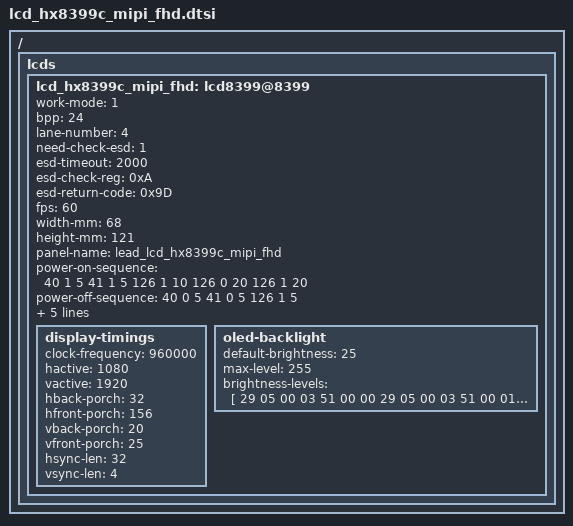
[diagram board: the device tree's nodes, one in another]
/ { lcds {
lcd_hx8399c_mipi_fhd: lcd8399@8399 {

		work-mode = <1>;
		bpp = <24>;
		lane-number = <4>;

		need-check-esd = <1>;
		esd-timeout = <2000>;
		esd-check-reg = <0xA>;
		esd-return-code = <0x9D>;

		fps = <60>;
		width-mm = <68>;
		height-mm = <121>;
		panel-name = "lead_lcd_hx8399c_mipi_fhd";

		power-on-sequence = <
				40  1  5
				41  1  5
				126  1  10
				126  0  20
				126  1  20
				>;
		power-off-sequence = <
				40  0  5
				41  0  5
				126  1  5
				>;

		init-data = [
			29 00 00 04 B9 FF 83 99
			29 00 00 05 BA 63 03 68 73
			29 00 00 10 B1 02 04 6D 8D 01 32 33 11 11 5E 64 56 73 02 02
			29 00 00 10 B2 07 00 80 AE 05 07 5A 31 10 30 00 1E 70 03 D4
			29 00 00 2D B4 00 FF 10 18 04 9A 00 00 06 00 02 04 00 24 02 04 0A 21 03 00 00 02 9F 88 10 18 04 9A 00 00 08 00 02 04 00 24 02 04 0A 00 00 02 9F 12
			29 00 00 22 D3 00 00 00 00 00 00 30 00 00 00 05 00 05 00 07 88 07 88 00 00 00 00 00 14 00 00 00 01 00 00 00 05 40
			29 00 00 21 D5 20 20 1E 1E 1F 1F 01 01 00 00 25 25 18 18 18 18 24 24 18 18 18 18 18 18 18 18 2F 2F 30 30 31 31
			29 00 00 21 D6 24 24 1E 1E 1F 1F 00 00 01 01 25 25 18 18 18 18 20 20 18 18 18 18 18 18 18 18 2F 2F 30 30 31 31
			23 00 00 02 BD 00
			29 00 00 11 D8 AA 8A AA AA AA 8A AA AA AA 8A AA AA AA 8A AA AA
			23 00 00 02 BD 01
			29 00 00 11 D8 FF CF EA BF FF CF EA BF FF CF EA BF FF CF EA BF
			23 00 00 02 BD 02
			29 00 00 09 D8 FF CF EA BF FF CF EA BF
			23 00 00 02 BD 00
			29 00 00 06 C9 03 00 12 20 31
			29 00 00 37 E0 02 1D 2B 25 54 5F 6C 69 72 7B 82 8A 90 98 9F A4 A5 AC AD B3 A4 AF B1 5B 59 65 7C 02 1D 2B 25 54 5F 6C 6A 73 7A 84 8B 90 96 9C 9F A0 A9 AC B2 A4 AF B1 5A 51 59 7C
			29 00 00 03 B6 8A 8A
			23 00 00 02 CC 08
			29 00 00 06 C7 00 08 00 01 08
			29 00 00 03 C0 25 5A
			29 00 00 08 BF 40 41 50 09 1A C0 CD
			23 0A 00 02 E4 01
			23 78 00 02 11 00
			23 14 00 02 29 00
			29 08 00 03 E4 01 02
			29 01 00 0A E5 00 04 0B 08 06 00 20 20 00
			29 01 00 0D E6 00 00 00 05 05 10 0A 10 20 20 00 00
			29 05 00 03 51 00 00
			23 05 00 02 55 01
			29 05 00 0A CA 24 24 24 23 23 20 20 20 20
			23 05 00 02 53 2C
			];
		sleep-in = [
			23 05 00 02 53 24
			29 00 00 04 B9 FF 83 99
			23 05 00 02 B1 00
			13 32 00 01 28
			13 A0 00 01 10
			29 00 00 04 B9 FF 83 99
			23 05 00 02 B1 01
			];
		sleep-out = [
			13 78 00 01 11
			13 32 00 01 29
			];

		display-timings {
			clock-frequency = <960000>;
			hactive = <1080>;
			vactive = <1920>;
			hback-porch = <32>;
			hfront-porch = <156>;
			vback-porch = <20>;
			vfront-porch = <25>;
			hsync-len = <32>;
			vsync-len = <4>;
		};
		oled-backlight {
			default-brightness = <25>;
			max-level = <255>;
			brightness-levels = [
				29 05 00 03 51 00 00
				29 05 00 03 51 00 01
				29 05 00 03 51 00 02
				29 05 00 03 51 00 03
				29 05 00 03 51 00 04
				29 05 00 03 51 00 06
				29 05 00 03 51 00 08
				29 05 00 03 51 00 0A
				29 05 00 03 51 00 0C
				29 05 00 03 51 00 0E
				29 05 00 03 51 00 10
				29 05 00 03 51 00 1A
				29 05 00 03 51 00 24
				29 05 00 03 51 00 2E
				29 05 00 03 51 00 39
				29 05 00 03 51 00 43
				29 05 00 03 51 00 4D
				29 05 00 03 51 00 58
				29 05 00 03 51 00 62
				29 05 00 03 51 00 6C
				29 05 00 03 51 00 76
				29 05 00 03 51 00 81
				29 05 00 03 51 00 8B
				29 05 00 03 51 00 95
				29 05 00 03 51 00 A0
				29 05 00 03 51 00 AA
				29 05 00 03 51 00 B4
				29 05 00 03 51 00 BE
				29 05 00 03 51 00 C9
				29 05 00 03 51 00 D3
				29 05 00 03 51 00 DD
				29 05 00 03 51 00 E8
				29 05 00 03 51 00 F2
				29 05 00 03 51 00 FC
				29 05 00 03 51 01 07
				29 05 00 03 51 01 11
				29 05 00 03 51 01 1B
				29 05 00 03 51 01 25
				29 05 00 03 51 01 30
				29 05 00 03 51 01 3A
				29 05 00 03 51 01 44
				29 05 00 03 51 01 4F
				29 05 00 03 51 01 59
				29 05 00 03 51 01 63
				29 05 00 03 51 01 6D
				29 05 00 03 51 01 78
				29 05 00 03 51 01 82
				29 05 00 03 51 01 8C
				29 05 00 03 51 01 97
				29 05 00 03 51 01 A1
				29 05 00 03 51 01 AB
				29 05 00 03 51 01 B6
				29 05 00 03 51 01 C0
				29 05 00 03 51 01 CA
				29 05 00 03 51 01 D4
				29 05 00 03 51 01 DF
				29 05 00 03 51 01 E9
				29 05 00 03 51 01 F3
				29 05 00 03 51 01 FE
				29 05 00 03 51 02 08
				29 05 00 03 51 02 12
				29 05 00 03 51 02 1C
				29 05 00 03 51 02 27
				29 05 00 03 51 02 31
				29 05 00 03 51 02 3B
				29 05 00 03 51 02 46
				29 05 00 03 51 02 50
				29 05 00 03 51 02 5A
				29 05 00 03 51 02 65
				29 05 00 03 51 02 6F
				29 05 00 03 51 02 79
				29 05 00 03 51 02 83
				29 05 00 03 51 02 8E
				29 05 00 03 51 02 98
				29 05 00 03 51 02 A2
				29 05 00 03 51 02 AD
				29 05 00 03 51 02 B7
				29 05 00 03 51 02 C1
				29 05 00 03 51 02 CB
				29 05 00 03 51 02 D6
				29 05 00 03 51 02 E0
				29 05 00 03 51 02 EA
				29 05 00 03 51 02 F5
				29 05 00 03 51 02 FF
				29 05 00 03 51 03 09
				29 05 00 03 51 03 14
				29 05 00 03 51 03 1E
				29 05 00 03 51 03 28
				29 05 00 03 51 03 32
				29 05 00 03 51 03 3D
				29 05 00 03 51 03 47
				29 05 00 03 51 03 51
				29 05 00 03 51 03 5C
				29 05 00 03 51 03 66
				29 05 00 03 51 03 70
				29 05 00 03 51 03 7A
				29 05 00 03 51 03 85
				29 05 00 03 51 03 8F
				29 05 00 03 51 03 99
				29 05 00 03 51 03 A4
				29 05 00 03 51 03 AE
				29 05 00 03 51 03 B8
				29 05 00 03 51 03 C3
				29 05 00 03 51 03 C9
				29 05 00 03 51 03 CF
				29 05 00 03 51 03 D6
				29 05 00 03 51 03 DC
				29 05 00 03 51 03 E3
				29 05 00 03 51 03 E9
				29 05 00 03 51 03 F0
				29 05 00 03 51 03 F6
				29 05 00 03 51 03 FC
				29 05 00 03 51 04 03
				29 05 00 03 51 04 09
				29 05 00 03 51 04 10
				29 05 00 03 51 04 16
				29 05 00 03 51 04 1D
				29 05 00 03 51 04 23
				29 05 00 03 51 04 2A
				29 05 00 03 51 04 30
				29 05 00 03 51 04 36
				29 05 00 03 51 04 3D
				29 05 00 03 51 04 43
				29 05 00 03 51 04 4A
				29 05 00 03 51 04 50
				29 05 00 03 51 04 57
				29 05 00 03 51 04 5D
				29 05 00 03 51 04 64
				29 05 00 03 51 04 71
				29 05 00 03 51 04 7F
				29 05 00 03 51 04 8D
				29 05 00 03 51 04 9B
				29 05 00 03 51 04 A8
				29 05 00 03 51 04 B6
				29 05 00 03 51 04 C4
				29 05 00 03 51 04 D2
				29 05 00 03 51 04 E0
				29 05 00 03 51 04 ED
				29 05 00 03 51 04 FB
				29 05 00 03 51 05 09
				29 05 00 03 51 05 17
				29 05 00 03 51 05 25
				29 05 00 03 51 05 32
				29 05 00 03 51 05 40
				29 05 00 03 51 05 4E
				29 05 00 03 51 05 5C
				29 05 00 03 51 05 6A
				29 05 00 03 51 05 77
				29 05 00 03 51 05 85
				29 05 00 03 51 05 93
				29 05 00 03 51 05 A1
				29 05 00 03 51 05 AF
				29 05 00 03 51 05 BC
				29 05 00 03 51 05 CA
				29 05 00 03 51 05 D8
				29 05 00 03 51 05 E6
				29 05 00 03 51 05 F4
				29 05 00 03 51 06 01
				29 05 00 03 51 06 0F
				29 05 00 03 51 06 1D
				29 05 00 03 51 06 2B
				29 05 00 03 51 06 39
				29 05 00 03 51 06 46
				29 05 00 03 51 06 54
				29 05 00 03 51 06 62
				29 05 00 03 51 06 70
				29 05 00 03 51 06 7E
				29 05 00 03 51 06 8B
				29 05 00 03 51 06 99
				29 05 00 03 51 06 A7
				29 05 00 03 51 06 B5
				29 05 00 03 51 06 C3
				29 05 00 03 51 06 D0
				29 05 00 03 51 06 DE
				29 05 00 03 51 06 EC
				29 05 00 03 51 06 FA
				29 05 00 03 51 07 08
				29 05 00 03 51 07 15
				29 05 00 03 51 07 23
				29 05 00 03 51 07 31
				29 05 00 03 51 07 3F
				29 05 00 03 51 07 4D
				29 05 00 03 51 07 5A
				29 05 00 03 51 07 68
				29 05 00 03 51 07 76
				29 05 00 03 51 07 84
				29 05 00 03 51 07 92
				29 05 00 03 51 07 9F
				29 05 00 03 51 07 AD
				29 05 00 03 51 07 BB
				29 05 00 03 51 07 C9
				29 05 00 03 51 07 D7
				29 05 00 03 51 07 E4
				29 05 00 03 51 07 F2
				29 05 00 03 51 08 00
				29 05 00 03 51 08 0E
				29 05 00 03 51 08 1B
				29 05 00 03 51 08 29
				29 05 00 03 51 08 37
				29 05 00 03 51 08 45
				29 05 00 03 51 08 53
				29 05 00 03 51 08 60
				29 05 00 03 51 08 6E
				29 05 00 03 51 08 7C
				29 05 00 03 51 08 8A
				29 05 00 03 51 08 98
				29 05 00 03 51 08 A5
				29 05 00 03 51 08 B3
				29 05 00 03 51 08 C1
				29 05 00 03 51 08 CF
				29 05 00 03 51 08 DD
				29 05 00 03 51 08 EA
				29 05 00 03 51 08 F8
				29 05 00 03 51 09 06
				29 05 00 03 51 09 14
				29 05 00 03 51 09 22
				29 05 00 03 51 09 2F
				29 05 00 03 51 09 3D
				29 05 00 03 51 09 4B
				29 05 00 03 51 09 59
				29 05 00 03 51 09 67
				29 05 00 03 51 09 74
				29 05 00 03 51 09 82
				29 05 00 03 51 09 90
				29 05 00 03 51 09 9E
				29 05 00 03 51 09 AC
				29 05 00 03 51 09 B9
				29 05 00 03 51 09 C7
				29 05 00 03 51 09 D5
				29 05 00 03 51 09 E3
				29 05 00 03 51 09 F1
				29 05 00 03 51 09 FE
				29 05 00 03 51 0A 0C
				29 05 00 03 51 0A 1A
				29 05 00 03 51 0A 28
				29 05 00 03 51 0A 36
				29 05 00 03 51 0A 43
				29 05 00 03 51 0A 51
				29 05 00 03 51 0A 5F
				29 05 00 03 51 0A 6D
				29 05 00 03 51 0A 7B
				29 05 00 03 51 0A 88
				29 05 00 03 51 0A 96
				29 05 00 03 51 0A A4
				29 05 00 03 51 0A B2
				29 05 00 03 51 0A C0
				29 05 00 03 51 0A CD
				29 05 00 03 51 0A DB
				29 05 00 03 51 0A E9
				29 05 00 03 51 0A F7
				29 05 00 03 51 0B 05
				29 05 00 03 51 0B 12
				29 05 00 03 51 0B 20
				29 05 00 03 51 0B 2E
				29 05 00 03 51 0B 3C
				29 05 00 03 51 0B 4A
			];
		};
	};
};};
